VERSION ""

NS_ :

BS_:

BU_: UserApplication MCM
VAL_TABLE_ Error_Type 255 "Other Error" 11 "Command Error" 10 "Password Error" 9 "Key Error" 8 "Count Error" 7 "Feedback Type Error" 6 "State Error" 5 "Permissions Error" 4 "Parameter ID Error" 3 "Interface ID Error" 2 "Section ID Error" 1 "CRC Error" 0 "No Error" ;
VAL_TABLE_ Config_SectionID 31 "Report" 11 "Relay" 10 "NLPID" 9 "PID" 8 "Signal" 7 "Heartbeat" 6 "Control" 5 "ClosedLoop" 4 "Override" 3 "Error" 2 "Fault" 1 "MCMGlobal" 0 "SygnalGlobal" ;

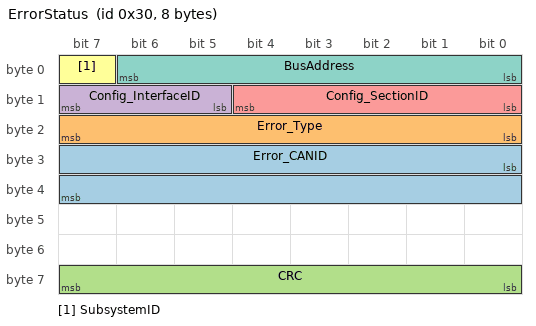
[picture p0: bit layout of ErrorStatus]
BO_ 48 ErrorStatus: 8 MCM
 SG_ Error_CANID : 24|16@1+ (1,0) [0|0] "" Vector__XXX
 SG_ Error_Type : 16|8@1+ (1,0) [0|0] "" Vector__XXX
 SG_ CRC : 56|8@1+ (1,0) [0|0] "" Vector__XXX
 SG_ Config_InterfaceID : 13|3@1+ (1,0) [0|0] "" Vector__XXX
 SG_ Config_SectionID : 8|5@1+ (1,0) [0|0] "" Vector__XXX
 SG_ SubsystemID : 7|1@1+ (1,0) [0|0] "" Vector__XXX
 SG_ BusAddress : 0|7@1+ (1,0) [0|0] "" Vector__XXX

BA_DEF_ SG_  "SigType" ENUM  "Default","Range","RangeSigned","ASCII","Discrete","Control","ReferencePGN","DTC","StringDelimiter","StringLength","StringLengthControl","MessageCounter","MessageChecksum";
BA_DEF_ SG_  "GenSigEVName" STRING ;
BA_DEF_ SG_  "GenSigILSupport" ENUM  "No","Yes";
BA_DEF_ SG_  "GenSigSendType" ENUM  "Cyclic","OnWrite","OnWriteWithRepetition","OnChange","OnChangeWithRepetition","IfActive","IfActiveWithRepetition","NoSigSendType";
BA_DEF_ BO_  "GenMsgILSupport" ENUM  "No","Yes";
BA_DEF_ BU_  "NmStationAddress" INT 0 255;
BA_DEF_ BO_  "GenMsgSendType" ENUM  "cyclic","NotUsed","IfActive","NotUsed","NotUsed","NotUsed","NotUsed","NotUsed","noMsgSendType";
BA_DEF_ BO_  "GenMsgRequestable" INT 0 1;
BA_DEF_  "DBName" STRING ;
BA_DEF_  "BusType" STRING ;
BA_DEF_  "ProtocolType" STRING ;
BA_DEF_ BO_  "VFrameFormat" ENUM  "StandardCAN","ExtendedCAN","reserved","J1939PG";
BA_DEF_DEF_  "SigType" "Default";
BA_DEF_DEF_  "GenSigEVName" "Env@Nodename_@Signame";
BA_DEF_DEF_  "GenSigILSupport" "Yes";
BA_DEF_DEF_  "GenSigSendType" "NoSigSendType";
BA_DEF_DEF_  "GenMsgILSupport" "Yes";
BA_DEF_DEF_  "NmStationAddress" 254;
BA_DEF_DEF_  "GenMsgSendType" "noMsgSendType";
BA_DEF_DEF_  "GenMsgRequestable" 1;
BA_DEF_DEF_  "DBName" "";
BA_DEF_DEF_  "BusType" "CAN";
BA_DEF_DEF_  "ProtocolType" "J1939";
BA_DEF_DEF_  "VFrameFormat" "J1939PG";
BA_ "DBName" "Configuration";
BA_ "NmStationAddress" BU_ UserApplication 241;
BA_ "NmStationAddress" BU_ MCM 0;
BA_ "VFrameFormat" BO_ 48 0;
VAL_ 48 Error_Type 255 "Other Error" 11 "Command Error" 10 "Password Error" 9 "Key Error" 8 "Count Error" 7 "Feedback Type Error" 6 "State Error" 5 "Permissions Error" 4 "Parameter ID Error" 3 "Interface ID Error" 2 "Section ID Error" 1 "CRC Error" 0 "No Error" ;
VAL_ 48 Config_SectionID 31 "Report" 11 "Relay" 10 "NLPID" 9 "PID" 8 "Signal" 7 "Heartbeat" 6 "Control" 5 "ClosedLoop" 4 "Override" 3 "Error" 2 "Fault" 1 "MCMGlobal" 0 "SygnalGlobal" ;
